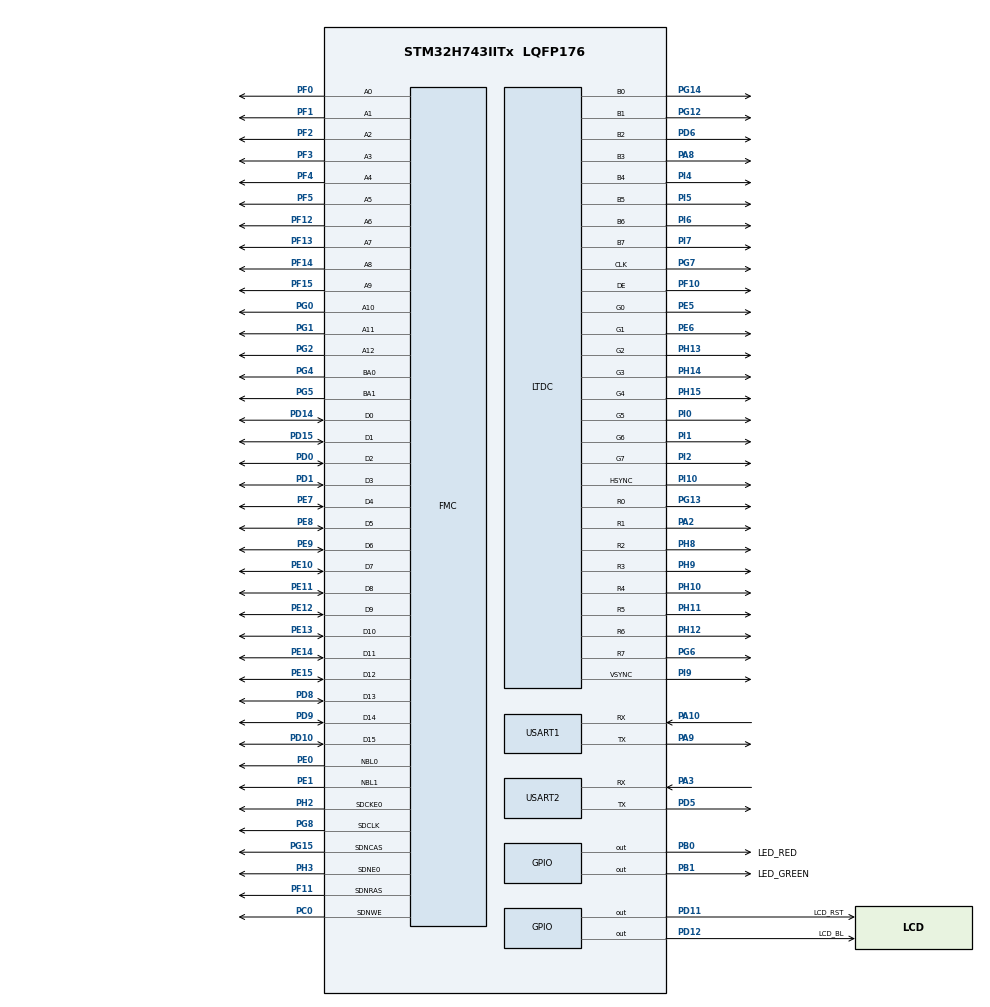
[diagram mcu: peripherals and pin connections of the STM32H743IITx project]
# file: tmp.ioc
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CORTEX_M7.AccessPermission_S-Cortex_Memory_Protection_Unit_Region1_Settings_S=MPU_REGION_FULL_ACCESS
CORTEX_M7.AccessPermission_Spec=MPU_REGION_FULL_ACCESS
CORTEX_M7.BaseAddress_S-Cortex_Memory_Protection_Unit_Region1_Settings_S=0x24000000
CORTEX_M7.BaseAddress_Spec=0xC0000000
CORTEX_M7.CPU_DCache=Enabled
CORTEX_M7.CPU_ICache=Enabled
CORTEX_M7.DisableExec_Spec=MPU_INSTRUCTION_ACCESS_ENABLE
CORTEX_M7.Enable_S-Cortex_Memory_Protection_Unit_Region1_Settings_S=MPU_REGION_ENABLE
CORTEX_M7.IsBufferable_S-Cortex_Memory_Protection_Unit_Region1_Settings_S=MPU_ACCESS_BUFFERABLE
CORTEX_M7.IsCacheable_S-Cortex_Memory_Protection_Unit_Region1_Settings_S=MPU_ACCESS_CACHEABLE
CORTEX_M7.IsShareable_S-Cortex_Memory_Protection_Unit_Region1_Settings_S=MPU_ACCESS_SHAREABLE
CORTEX_M7.Size_S-Cortex_Memory_Protection_Unit_Region1_Settings_S=MPU_REGION_SIZE_512KB
CORTEX_M7.Size_Spec=MPU_REGION_SIZE_32MB
CORTEX_M7.SubRegionDisable_Spec=0x0
CORTEX_M7.default_mode_Activation=1
DMA2D.ColorMode=DMA2D_OUTPUT_RGB565
FMC.CASLatency1=FMC_SDRAM_CAS_LATENCY_3
FMC.ColumnBitsNumber1=FMC_SDRAM_COLUMN_BITS_NUM_9
FMC.ExitSelfRefreshDelay1=9
FMC.LoadToActiveDelay1=2
FMC.RCDDelay1=2
FMC.RPDelay1=2
FMC.ReadBurst1=FMC_SDRAM_RBURST_ENABLE
FMC.ReadPipeDelay1=FMC_SDRAM_RPIPE_DELAY_1
FMC.RowCycleDelay1=8
FMC.SDClockPeriod1=FMC_SDRAM_CLOCK_PERIOD_2
FMC.SelfRefreshTime1=6
FMC.WriteRecoveryTime1=5
LTDC.ActiveH=1280
LTDC.ActiveW=800
LTDC.Alpha0_L0=255
LTDC.Alpha_L0=255
LTDC.Blue=0
LTDC.Blue_L0=0
LTDC.FBStartAdress_L0=0xC0000000
LTDC.Green=0
LTDC.Green_L0=0
LTDC.HBP=20
LTDC.HFP=40
LTDC.HSync=5
LTDC.ImageHeight_L0=1280
LTDC.ImageWidth_L0=800
LTDC.Layers=0
LTDC.PixelFormat_L0=LTDC_PIXEL_FORMAT_RGB565
LTDC.Red=0
LTDC.Red_L0=0
LTDC.VBP=20
LTDC.VFP=30
LTDC.VSync=3
LTDC.WindowX1_L0=800
LTDC.WindowY1_L0=1280
Mcu.Family=STM32H7
Mcu.Name=STM32H743IITx
Mcu.Package=LQFP176
NVIC.DMA2D_IRQn=true\:0\:0\:false\:false\:true\:true\:true\:true
NVIC.PriorityGroup=NVIC_PRIORITYGROUP_3
PA10.GPIO_Speed=GPIO_SPEED_FREQ_HIGH
PA10.Mode=Asynchronous
PA10.Signal=USART1_RX
PA2.GPIO_Speed=GPIO_SPEED_FREQ_VERY_HIGH
PA2.Mode=RGB888
PA2.Signal=LTDC_R1
PA3.GPIO_Speed=GPIO_SPEED_FREQ_HIGH
PA3.Mode=Asynchronous
PA3.Signal=USART2_RX
PA8.GPIO_Speed=GPIO_SPEED_FREQ_VERY_HIGH
PA8.Mode=RGB888
PA8.Signal=LTDC_B3
PA9.GPIO_Speed=GPIO_SPEED_FREQ_HIGH
PA9.Mode=Asynchronous
PA9.Signal=USART1_TX
PB0.GPIO_Label=LED_RED
PB0.GPIO_Speed=GPIO_SPEED_FREQ_LOW
PB0.PinState=GPIO_PIN_RESET
PB0.Signal=GPIO_Output
PB1.GPIO_Label=LED_GREEN
PB1.Signal=GPIO_Output
PC0.Signal=FMC_SDNWE
PC14-OSC32_IN\ (OSC32_IN).Mode=LSE-External-Oscillator
PC14-OSC32_IN\ (OSC32_IN).Signal=RCC_OSC32_IN
PC15-OSC32_OUT\ (OSC32_OUT).Mode=LSE-External-Oscillator
PC15-OSC32_OUT\ (OSC32_OUT).Signal=RCC_OSC32_OUT
PD0.Signal=FMC_D2_DA2
PD1.Signal=FMC_D3_DA3
PD10.Signal=FMC_D15_DA15
PD11.GPIO_Label=LCD_RST
PD11.PinState=GPIO_PIN_SET
PD11.Signal=GPIO_Output
PD12.GPIO_Label=LCD_BL
PD12.Signal=GPIO_Output
PD14.Signal=FMC_D0_DA0
PD15.Signal=FMC_D1_DA1
PD5.GPIO_Speed=GPIO_SPEED_FREQ_HIGH
PD5.Mode=Asynchronous
PD5.Signal=USART2_TX
PD6.GPIO_Speed=GPIO_SPEED_FREQ_VERY_HIGH
PD6.Mode=RGB888
PD6.Signal=LTDC_B2
PD8.Signal=FMC_D13_DA13
PD9.Signal=FMC_D14_DA14
PE0.Signal=FMC_NBL0
PE1.Signal=FMC_NBL1
PE10.Signal=FMC_D7_DA7
PE11.Signal=FMC_D8_DA8
PE12.Signal=FMC_D9_DA9
PE13.Signal=FMC_D10_DA10
PE14.Signal=FMC_D11_DA11
PE15.Signal=FMC_D12_DA12
PE5.GPIO_Speed=GPIO_SPEED_FREQ_VERY_HIGH
PE5.Mode=RGB888
PE5.Signal=LTDC_G0
PE6.GPIO_Speed=GPIO_SPEED_FREQ_VERY_HIGH
PE6.Mode=RGB888
PE6.Signal=LTDC_G1
PE7.Signal=FMC_D4_DA4
PE8.Signal=FMC_D5_DA5
PE9.Signal=FMC_D6_DA6
PF0.Signal=FMC_A0
PF1.Signal=FMC_A1
PF10.GPIO_Speed=GPIO_SPEED_FREQ_VERY_HIGH
PF10.Mode=RGB888
PF10.Signal=LTDC_DE
PF11.Signal=FMC_SDNRAS
PF12.Signal=FMC_A6
PF13.Signal=FMC_A7
PF14.Signal=FMC_A8
PF15.Signal=FMC_A9
PF2.Signal=FMC_A2
PF3.Signal=FMC_A3
PF4.Signal=FMC_A4
PF5.Signal=FMC_A5
PG0.Signal=FMC_A10
PG1.Signal=FMC_A11
PG12.GPIO_Speed=GPIO_SPEED_FREQ_VERY_HIGH
PG12.Mode=RGB888
PG12.Signal=LTDC_B1
PG13.GPIO_Speed=GPIO_SPEED_FREQ_VERY_HIGH
PG13.Mode=RGB888
PG13.Signal=LTDC_R0
PG14.GPIO_Speed=GPIO_SPEED_FREQ_VERY_HIGH
PG14.Mode=RGB888
PG14.Signal=LTDC_B0
PG15.Signal=FMC_SDNCAS
PG2.Signal=FMC_A12
PG4.Signal=FMC_A14_BA0
PG5.Signal=FMC_A15_BA1
PG6.GPIO_Speed=GPIO_SPEED_FREQ_VERY_HIGH
PG6.Mode=RGB888
PG6.Signal=LTDC_R7
PG7.GPIO_Speed=GPIO_SPEED_FREQ_VERY_HIGH
PG7.Mode=RGB888
PG7.Signal=LTDC_CLK
PG8.Signal=FMC_SDCLK
PH0-OSC_IN\ (PH0).Mode=HSE-External-Oscillator
PH0-OSC_IN\ (PH0).Signal=RCC_OSC_IN
PH1-OSC_OUT\ (PH1).Mode=HSE-External-Oscillator
PH1-OSC_OUT\ (PH1).Signal=RCC_OSC_OUT
PH10.GPIO_Speed=GPIO_SPEED_FREQ_VERY_HIGH
PH10.Mode=RGB888
PH10.Signal=LTDC_R4
PH11.GPIO_Speed=GPIO_SPEED_FREQ_VERY_HIGH
PH11.Mode=RGB888
PH11.Signal=LTDC_R5
PH12.GPIO_Speed=GPIO_SPEED_FREQ_VERY_HIGH
PH12.Mode=RGB888
PH12.Signal=LTDC_R6
PH13.GPIO_Speed=GPIO_SPEED_FREQ_VERY_HIGH
PH13.Mode=RGB888
PH13.Signal=LTDC_G2
PH14.GPIO_Speed=GPIO_SPEED_FREQ_VERY_HIGH
PH14.Mode=RGB888
PH14.Signal=LTDC_G3
PH15.GPIO_Speed=GPIO_SPEED_FREQ_VERY_HIGH
PH15.Mode=RGB888
PH15.Signal=LTDC_G4
PH2.Mode=SdramChipSelect1_1
PH2.Signal=FMC_SDCKE0
PH3.Mode=SdramChipSelect1_1
PH3.Signal=FMC_SDNE0
PH8.GPIO_Speed=GPIO_SPEED_FREQ_VERY_HIGH
PH8.Mode=RGB888
PH8.Signal=LTDC_R2
PH9.GPIO_Speed=GPIO_SPEED_FREQ_VERY_HIGH
PH9.Mode=RGB888
PH9.Signal=LTDC_R3
PI0.GPIO_Speed=GPIO_SPEED_FREQ_VERY_HIGH
PI0.Mode=RGB888
PI0.Signal=LTDC_G5
PI1.GPIO_Speed=GPIO_SPEED_FREQ_VERY_HIGH
PI1.Mode=RGB888
PI1.Signal=LTDC_G6
PI10.GPIO_Speed=GPIO_SPEED_FREQ_VERY_HIGH
PI10.Mode=RGB888
PI10.Signal=LTDC_HSYNC
PI2.GPIO_Speed=GPIO_SPEED_FREQ_VERY_HIGH
PI2.Mode=RGB888
PI2.Signal=LTDC_G7
PI4.GPIO_Speed=GPIO_SPEED_FREQ_VERY_HIGH
PI4.Mode=RGB888
PI4.Signal=LTDC_B4
PI5.GPIO_Speed=GPIO_SPEED_FREQ_VERY_HIGH
PI5.Mode=RGB888
PI5.Signal=LTDC_B5
PI6.GPIO_Speed=GPIO_SPEED_FREQ_VERY_HIGH
PI6.Mode=RGB888
PI6.Signal=LTDC_B6
PI7.GPIO_Speed=GPIO_SPEED_FREQ_VERY_HIGH
PI7.Mode=RGB888
PI7.Signal=LTDC_B7
PI9.GPIO_Speed=GPIO_SPEED_FREQ_VERY_HIGH
PI9.Mode=RGB888
PI9.Signal=LTDC_VSYNC
ProjectManager.HeapSize=0x0
ProjectManager.StackSize=0x1000
ProjectManager.TargetToolchain=CMake
RCC.ADCFreq_Value=50390625
RCC.APB1Freq_Value=120000000
RCC.APB2Freq_Value=120000000
RCC.APB3Freq_Value=120000000
RCC.APB4Freq_Value=120000000
RCC.CortexFreq_Value=480000000
RCC.D1PPRE=RCC_APB3_DIV2
RCC.D2PPRE1=RCC_APB1_DIV2
RCC.D2PPRE2=RCC_APB2_DIV2
RCC.D3PPRE=RCC_APB4_DIV2
RCC.DIVM1=5
RCC.DIVM3=1
RCC.DIVN1=192
RCC.DIVN3=8
RCC.DIVR3=5
RCC.EnbaleCSS=true
RCC.HCLKFreq_Value=240000000
RCC.HPRE=RCC_HCLK_DIV2
RCC.PLLSourceVirtual=RCC_PLLSOURCE_HSE
RCC.SYSCLKFreq_VALUE=480000000
RCC.SYSCLKSource=RCC_SYSCLKSOURCE_PLLCLK
RCC.USBFreq_Value=480000000
SH.FMC_A0.0=FMC_A0,13b-sda1
SH.FMC_A1.0=FMC_A1,13b-sda1
SH.FMC_A10.0=FMC_A10,13b-sda1
SH.FMC_A11.0=FMC_A11,13b-sda1
SH.FMC_A12.0=FMC_A12,13b-sda1
SH.FMC_A14_BA0.0=FMC_BA0,FourSdramBanks1
SH.FMC_A15_BA1.0=FMC_BA1,FourSdramBanks1
SH.FMC_A2.0=FMC_A2,13b-sda1
SH.FMC_A3.0=FMC_A3,13b-sda1
SH.FMC_A4.0=FMC_A4,13b-sda1
SH.FMC_A5.0=FMC_A5,13b-sda1
SH.FMC_A6.0=FMC_A6,13b-sda1
SH.FMC_A7.0=FMC_A7,13b-sda1
SH.FMC_A8.0=FMC_A8,13b-sda1
SH.FMC_A9.0=FMC_A9,13b-sda1
SH.FMC_D0_DA0.0=FMC_D0,sd-16b-d1
SH.FMC_D10_DA10.0=FMC_D10,sd-16b-d1
SH.FMC_D11_DA11.0=FMC_D11,sd-16b-d1
SH.FMC_D12_DA12.0=FMC_D12,sd-16b-d1
SH.FMC_D13_DA13.0=FMC_D13,sd-16b-d1
SH.FMC_D14_DA14.0=FMC_D14,sd-16b-d1
SH.FMC_D15_DA15.0=FMC_D15,sd-16b-d1
SH.FMC_D1_DA1.0=FMC_D1,sd-16b-d1
SH.FMC_D2_DA2.0=FMC_D2,sd-16b-d1
SH.FMC_D3_DA3.0=FMC_D3,sd-16b-d1
SH.FMC_D4_DA4.0=FMC_D4,sd-16b-d1
SH.FMC_D5_DA5.0=FMC_D5,sd-16b-d1
SH.FMC_D6_DA6.0=FMC_D6,sd-16b-d1
SH.FMC_D7_DA7.0=FMC_D7,sd-16b-d1
SH.FMC_D8_DA8.0=FMC_D8,sd-16b-d1
SH.FMC_D9_DA9.0=FMC_D9,sd-16b-d1
SH.FMC_NBL0.0=FMC_NBL0,Sd2ByteEnable1
SH.FMC_NBL1.0=FMC_NBL1,Sd2ByteEnable1
SH.FMC_SDCLK.0=FMC_SDCLK,13b-sda1
SH.FMC_SDNCAS.0=FMC_SDNCAS,13b-sda1
SH.FMC_SDNRAS.0=FMC_SDNRAS,13b-sda1
SH.FMC_SDNWE.0=FMC_SDNWE,13b-sda1
USART1.VirtualMode-Asynchronous=VM_ASYNC
USART2.VirtualMode-Asynchronous=VM_ASYNC
VP_DMA2D_VS_DMA2D.Mode=DMA2D_Activate
VP_MEMORYMAP_VS_MEMORYMAP.Mode=CurAppReg
board=custom

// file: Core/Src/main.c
/* USER CODE BEGIN Header */
/**
 ******************************************************************************
 * @file           : main.c
 * @brief          : Main program body
 ******************************************************************************
 * @attention
 *
 * Copyright (c) 2025 STMicroelectronics.
 * All rights reserved.
 *
 * This software is licensed under terms that can be found in the LICENSE file
 * in the root directory of this software component.
 * If no LICENSE file comes with this software, it is provided AS-IS.
 *
 ******************************************************************************
 */
/* USER CODE END Header */
#include "main.h"
#include "dma2d.h"
#include "ltdc.h"
#include "usart.h"
#include "gpio.h"
#include "fmc.h"

/* USER CODE BEGIN Includes */
#include <board.h>
/* USER CODE END Includes */

void SystemClock_Config(void);
void PeriphCommonClock_Config(void);
static void MPU_Config(void);

int main(void)
{

  /* MPU Configuration--------------------------------------------------------*/
  MPU_Config();

  /* Enable the CPU Cache */

  /* Enable I-Cache---------------------------------------------------------*/
  SCB_EnableICache();

  /* Enable D-Cache---------------------------------------------------------*/
  SCB_EnableDCache();

  /* MCU Configuration--------------------------------------------------------*/

  /* Reset of all peripherals, Initializes the Flash interface and the Systick. */
  HAL_Init();

  /* Configure the system clock */
  SystemClock_Config();

  /* Configure the peripherals common clocks */
  PeriphCommonClock_Config();

  /* USER CODE BEGIN SysInit */
#if 0
  /* USER CODE END SysInit */

  /* Initialize all configured peripherals */
  MX_GPIO_Init();
  MX_USART1_UART_Init();
  MX_FMC_Init();
  MX_USART2_UART_Init();
  MX_LTDC_Init();
  MX_DMA2D_Init();
  /* USER CODE BEGIN 2 */
#endif
    MX_GPIO_Init();
    MX_USART1_UART_Init();
    MX_USART2_UART_Init();
    MX_FMC_Init();
    sdram_init();
    lv_init();
    lv_port_disp_init();
    MX_LTDC_Init();
    MX_DMA2D_Init();
    ui_init();
  /* USER CODE END 2 */

  /* Infinite loop */
  /* USER CODE BEGIN WHILE */
    while (1)
    {
        LL_GPIO_TogglePin(LED_RED_GPIO_Port, LED_RED_Pin);
        LL_GPIO_TogglePin(LED_GREEN_GPIO_Port, LED_GREEN_Pin);
        lv_timer_handler();
        LL_mDelay(1);
    /* USER CODE END WHILE */

    }
}

void SystemClock_Config(void)
{
  LL_FLASH_SetLatency(LL_FLASH_LATENCY_4);
  while(LL_FLASH_GetLatency()!= LL_FLASH_LATENCY_4)
  {
  }
  LL_PWR_ConfigSupply(LL_PWR_LDO_SUPPLY);
  LL_PWR_SetRegulVoltageScaling(LL_PWR_REGU_VOLTAGE_SCALE0);
  while (LL_PWR_IsActiveFlag_VOS() == 0)
  {
  }
  LL_RCC_HSE_Enable();

   /* Wait till HSE is ready */
  while(LL_RCC_HSE_IsReady() != 1)
  {

  }
  LL_RCC_HSE_EnableCSS();
  LL_RCC_PLL_SetSource(LL_RCC_PLLSOURCE_HSE);
  LL_RCC_PLL1P_Enable();
  LL_RCC_PLL1_SetVCOInputRange(LL_RCC_PLLINPUTRANGE_4_8);
  LL_RCC_PLL1_SetVCOOutputRange(LL_RCC_PLLVCORANGE_WIDE);
  LL_RCC_PLL1_SetM(5);
  LL_RCC_PLL1_SetN(192);
  LL_RCC_PLL1_SetP(2);
  LL_RCC_PLL1_SetQ(2);
  LL_RCC_PLL1_SetR(2);
  LL_RCC_PLL1_Enable();

   /* Wait till PLL is ready */
  while(LL_RCC_PLL1_IsReady() != 1)
  {
  }

   /* Intermediate AHB prescaler 2 when target frequency clock is higher than 80 MHz */
   LL_RCC_SetAHBPrescaler(LL_RCC_AHB_DIV_2);

  LL_RCC_SetSysClkSource(LL_RCC_SYS_CLKSOURCE_PLL1);

   /* Wait till System clock is ready */
  while(LL_RCC_GetSysClkSource() != LL_RCC_SYS_CLKSOURCE_STATUS_PLL1)
  {

  }
  LL_RCC_SetSysPrescaler(LL_RCC_SYSCLK_DIV_1);
  LL_RCC_SetAHBPrescaler(LL_RCC_AHB_DIV_2);
  LL_RCC_SetAPB1Prescaler(LL_RCC_APB1_DIV_2);
  LL_RCC_SetAPB2Prescaler(LL_RCC_APB2_DIV_2);
  LL_RCC_SetAPB3Prescaler(LL_RCC_APB3_DIV_2);
  LL_RCC_SetAPB4Prescaler(LL_RCC_APB4_DIV_2);
  LL_SetSystemCoreClock(480000000);

   /* Update the time base */
  if (HAL_InitTick (TICK_INT_PRIORITY) != HAL_OK)
  {
    Error_Handler();
  }
  LL_RCC_HSE_EnableCSS();
}

void PeriphCommonClock_Config(void)
{
  LL_RCC_PLL3R_Enable();
  LL_RCC_PLL3_SetVCOInputRange(LL_RCC_PLLINPUTRANGE_8_16);
  LL_RCC_PLL3_SetVCOOutputRange(LL_RCC_PLLVCORANGE_WIDE);
  LL_RCC_PLL3_SetM(1);
  LL_RCC_PLL3_SetN(8);
  LL_RCC_PLL3_SetP(2);
  LL_RCC_PLL3_SetQ(2);
  LL_RCC_PLL3_SetR(5);
  LL_RCC_PLL3_Enable();

   /* Wait till PLL is ready */
  while(LL_RCC_PLL3_IsReady() != 1)
  {
  }

}

 /* MPU Configuration */

void MPU_Config(void)
{

  /* Disables the MPU */
  LL_MPU_Disable();

  /** Initializes and configures the Region and the memory to be protected
  */
  LL_MPU_ConfigRegion(LL_MPU_REGION_NUMBER0, 0x0, 0xC0000000, LL_MPU_REGION_SIZE_32MB|LL_MPU_TEX_LEVEL0|LL_MPU_REGION_FULL_ACCESS|LL_MPU_INSTRUCTION_ACCESS_ENABLE|LL_MPU_ACCESS_SHAREABLE|LL_MPU_ACCESS_NOT_CACHEABLE|LL_MPU_ACCESS_NOT_BUFFERABLE);

  /** Initializes and configures the Region and the memory to be protected
  */
  LL_MPU_ConfigRegion(LL_MPU_REGION_NUMBER1, 0x0, 0x24000000, LL_MPU_REGION_SIZE_512KB|LL_MPU_TEX_LEVEL0|LL_MPU_REGION_FULL_ACCESS|LL_MPU_INSTRUCTION_ACCESS_ENABLE|LL_MPU_ACCESS_SHAREABLE|LL_MPU_ACCESS_CACHEABLE|LL_MPU_ACCESS_BUFFERABLE);
  /* Enables the MPU */
  LL_MPU_Enable(LL_MPU_CTRL_PRIVILEGED_DEFAULT);

}

void Error_Handler(void)
{
    __disable_irq();
    while (1)
    {
    }
}
